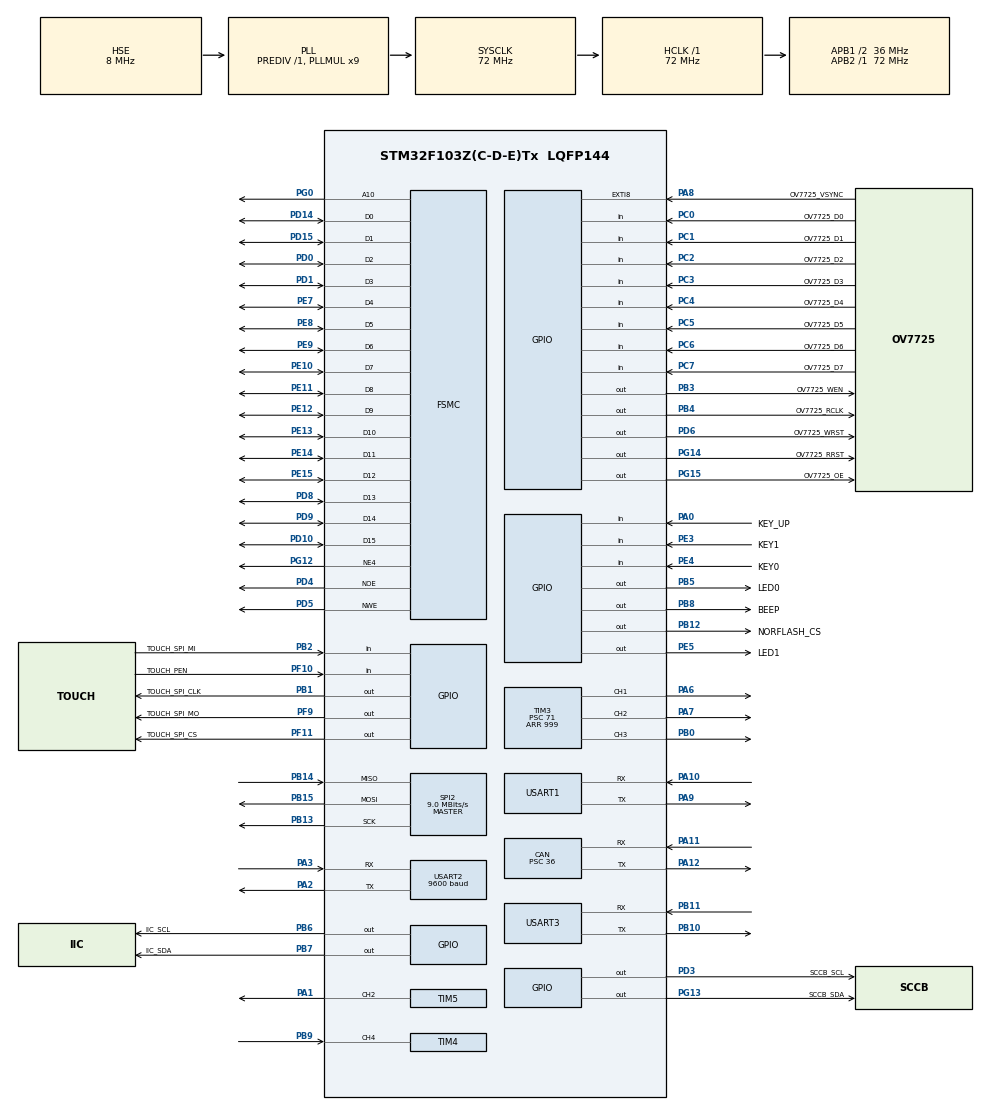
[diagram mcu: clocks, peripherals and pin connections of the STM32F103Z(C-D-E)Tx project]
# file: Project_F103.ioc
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CAN.ABOM=ENABLE
CAN.AWUM=ENABLE
CAN.BS1=CAN_BS1_2TQ
CAN.BS2=CAN_BS2_2TQ
CAN.CalculateBaudRate=200000
CAN.CalculateTimeBit=5000
CAN.CalculateTimeQuantum=1000.0
CAN.Mode=CAN_MODE_NORMAL
CAN.Prescaler=36
Dma.Request0=USART1_RX
Dma.Request1=USART1_TX
Dma.Request2=USART2_RX
Dma.Request3=USART2_TX
Dma.Request4=USART3_RX
Dma.Request5=USART3_TX
Dma.USART1_RX.0.Direction=DMA_PERIPH_TO_MEMORY
Dma.USART1_RX.0.Instance=DMA1_Channel5
Dma.USART1_RX.0.MemDataAlignment=DMA_MDATAALIGN_BYTE
Dma.USART1_RX.0.MemInc=DMA_MINC_ENABLE
Dma.USART1_RX.0.Mode=DMA_NORMAL
Dma.USART1_RX.0.PeriphDataAlignment=DMA_PDATAALIGN_BYTE
Dma.USART1_RX.0.PeriphInc=DMA_PINC_DISABLE
Dma.USART1_RX.0.Priority=DMA_PRIORITY_LOW
Dma.USART1_TX.1.Direction=DMA_MEMORY_TO_PERIPH
Dma.USART1_TX.1.Instance=DMA1_Channel4
Dma.USART1_TX.1.MemDataAlignment=DMA_MDATAALIGN_BYTE
Dma.USART1_TX.1.MemInc=DMA_MINC_ENABLE
Dma.USART1_TX.1.Mode=DMA_NORMAL
Dma.USART1_TX.1.PeriphDataAlignment=DMA_PDATAALIGN_BYTE
Dma.USART1_TX.1.PeriphInc=DMA_PINC_DISABLE
Dma.USART1_TX.1.Priority=DMA_PRIORITY_LOW
Dma.USART2_RX.2.Direction=DMA_PERIPH_TO_MEMORY
Dma.USART2_RX.2.Instance=DMA1_Channel6
Dma.USART2_RX.2.MemDataAlignment=DMA_MDATAALIGN_BYTE
Dma.USART2_RX.2.MemInc=DMA_MINC_ENABLE
Dma.USART2_RX.2.Mode=DMA_NORMAL
Dma.USART2_RX.2.PeriphDataAlignment=DMA_PDATAALIGN_BYTE
Dma.USART2_RX.2.PeriphInc=DMA_PINC_DISABLE
Dma.USART2_RX.2.Priority=DMA_PRIORITY_LOW
Dma.USART2_TX.3.Direction=DMA_MEMORY_TO_PERIPH
Dma.USART2_TX.3.Instance=DMA1_Channel7
Dma.USART2_TX.3.MemDataAlignment=DMA_MDATAALIGN_BYTE
Dma.USART2_TX.3.MemInc=DMA_MINC_ENABLE
Dma.USART2_TX.3.Mode=DMA_NORMAL
Dma.USART2_TX.3.PeriphDataAlignment=DMA_PDATAALIGN_BYTE
Dma.USART2_TX.3.PeriphInc=DMA_PINC_DISABLE
Dma.USART2_TX.3.Priority=DMA_PRIORITY_LOW
Dma.USART3_RX.4.Direction=DMA_PERIPH_TO_MEMORY
Dma.USART3_RX.4.Instance=DMA1_Channel3
Dma.USART3_RX.4.MemDataAlignment=DMA_MDATAALIGN_BYTE
Dma.USART3_RX.4.MemInc=DMA_MINC_ENABLE
Dma.USART3_RX.4.Mode=DMA_NORMAL
Dma.USART3_RX.4.PeriphDataAlignment=DMA_PDATAALIGN_BYTE
Dma.USART3_RX.4.PeriphInc=DMA_PINC_DISABLE
Dma.USART3_RX.4.Priority=DMA_PRIORITY_LOW
Dma.USART3_TX.5.Direction=DMA_MEMORY_TO_PERIPH
Dma.USART3_TX.5.Instance=DMA1_Channel2
Dma.USART3_TX.5.MemDataAlignment=DMA_MDATAALIGN_BYTE
Dma.USART3_TX.5.MemInc=DMA_MINC_ENABLE
Dma.USART3_TX.5.Mode=DMA_NORMAL
Dma.USART3_TX.5.PeriphDataAlignment=DMA_PDATAALIGN_BYTE
Dma.USART3_TX.5.PeriphInc=DMA_PINC_DISABLE
Dma.USART3_TX.5.Priority=DMA_PRIORITY_LOW
FSMC.AddressSetupTime1=0
FSMC.BusTurnAroundDuration1=0
FSMC.DataSetupTime1=15
FSMC.ExtendedAddressSetupTime1=0
FSMC.ExtendedBusTurnAroundDuration1=0
FSMC.ExtendedDataSetupTime1=1
FSMC.ExtendedMode1=FSMC_EXTENDED_MODE_ENABLE
FSMC.WriteOperation1=FSMC_WRITE_OPERATION_ENABLE
IWDG.Prescaler=IWDG_PRESCALER_32
Mcu.Family=STM32F1
Mcu.Name=STM32F103Z(C-D-E)Tx
Mcu.Package=LQFP144
NVIC.CAN1_RX1_IRQn=true\:6\:0\:true\:false\:true\:true\:true\:true
NVIC.DMA1_Channel2_IRQn=true\:0\:0\:false\:false\:true\:false\:true\:true
NVIC.DMA1_Channel3_IRQn=true\:0\:0\:false\:false\:true\:false\:true\:true
NVIC.DMA1_Channel4_IRQn=true\:0\:0\:false\:false\:true\:false\:true\:true
NVIC.DMA1_Channel5_IRQn=true\:0\:0\:false\:false\:true\:false\:true\:true
NVIC.DMA1_Channel6_IRQn=true\:0\:0\:false\:false\:true\:false\:true\:true
NVIC.DMA1_Channel7_IRQn=true\:0\:0\:false\:false\:true\:false\:true\:true
NVIC.EXTI9_5_IRQn=true\:7\:0\:true\:false\:true\:true\:true\:true
NVIC.PriorityGroup=NVIC_PRIORITYGROUP_4
NVIC.TIM4_IRQn=true\:6\:0\:true\:false\:true\:true\:true\:true
NVIC.TIM6_IRQn=true\:15\:0\:false\:false\:true\:false\:true\:true
NVIC.TimeBase=TIM6_IRQn
NVIC.TimeBaseIP=TIM6
NVIC.USART1_IRQn=true\:6\:0\:true\:false\:true\:false\:true\:true
NVIC.USART2_IRQn=true\:6\:0\:true\:false\:true\:true\:true\:true
NVIC.USART3_IRQn=true\:6\:0\:true\:false\:true\:true\:true\:true
NVIC.USB_LP_CAN1_RX0_IRQn=true\:6\:0\:true\:false\:true\:true\:true\:true
OSC_IN.Mode=HSE-External-Oscillator
OSC_IN.Signal=RCC_OSC_IN
OSC_OUT.Mode=HSE-External-Oscillator
OSC_OUT.Signal=RCC_OSC_OUT
PA0-WKUP.GPIO_Label=KEY_UP
PA0-WKUP.GPIO_PuPd=GPIO_PULLUP
PA0-WKUP.Signal=GPIO_Input
PA1.Signal=S_TIM5_CH2
PA10.Mode=Asynchronous
PA10.Signal=USART1_RX
PA11.Mode=CAN_Activate
PA11.Signal=CAN_RX
PA12.Mode=CAN_Activate
PA12.Signal=CAN_TX
PA13.Mode=Serial_Wire
PA13.Signal=SYS_JTMS-SWDIO
PA14.Mode=Serial_Wire
PA14.Signal=SYS_JTCK-SWCLK
PA2.Mode=Asynchronous
PA2.Signal=USART2_TX
PA3.Mode=Asynchronous
PA3.Signal=USART2_RX
PA6.Signal=S_TIM3_CH1
PA7.Signal=S_TIM3_CH2
PA8.GPIO_Label=OV7725_VSYNC
PA8.Signal=GPXTI8
PA9.Mode=Asynchronous
PA9.Signal=USART1_TX
PB0.Signal=S_TIM3_CH3
PB1.GPIO_Label=TOUCH_SPI_CLK
PB1.GPIO_ModeDefaultOutputPP=GPIO_MODE_OUTPUT_PP
PB1.GPIO_PuPd=GPIO_PULLUP
PB1.GPIO_Speed=GPIO_SPEED_FREQ_HIGH
PB1.PinState=GPIO_PIN_SET
PB1.Signal=GPIO_Output
PB10.Mode=Asynchronous
PB10.Signal=USART3_TX
PB11.Mode=Asynchronous
PB11.Signal=USART3_RX
PB12.GPIO_Label=NORFLASH_CS
PB12.GPIO_ModeDefaultOutputPP=GPIO_MODE_OUTPUT_PP
PB12.GPIO_PuPd=GPIO_PULLUP
PB12.GPIO_Speed=GPIO_SPEED_FREQ_HIGH
PB12.PinState=GPIO_PIN_SET
PB12.Signal=GPIO_Output
PB13.Mode=Full_Duplex_Master
PB13.Signal=SPI2_SCK
PB14.Mode=Full_Duplex_Master
PB14.Signal=SPI2_MISO
PB15.Mode=Full_Duplex_Master
PB15.Signal=SPI2_MOSI
PB2.GPIO_Label=TOUCH_SPI_MI
PB2.GPIO_PuPd=GPIO_PULLUP
PB2.Signal=GPIO_Input
PB3.GPIO_Label=OV7725_WEN
PB3.GPIO_ModeDefaultOutputPP=GPIO_MODE_OUTPUT_PP
PB3.GPIO_PuPd=GPIO_PULLUP
PB3.GPIO_Speed=GPIO_SPEED_FREQ_HIGH
PB3.PinState=GPIO_PIN_SET
PB3.Signal=GPIO_Output
PB4.GPIO_Label=OV7725_RCLK
PB4.GPIO_ModeDefaultOutputPP=GPIO_MODE_OUTPUT_PP
PB4.GPIO_PuPd=GPIO_PULLUP
PB4.GPIO_Speed=GPIO_SPEED_FREQ_HIGH
PB4.PinState=GPIO_PIN_SET
PB4.Signal=GPIO_Output
PB5.GPIO_Label=LED0
PB5.GPIO_PuPd=GPIO_NOPULL
PB5.PinState=GPIO_PIN_SET
PB5.Signal=GPIO_Output
PB6.GPIO_Label=IIC_SCL
PB6.GPIO_ModeDefaultOutputPP=GPIO_MODE_OUTPUT_OD
PB6.GPIO_PuPd=GPIO_NOPULL
PB6.GPIO_Speed=GPIO_SPEED_FREQ_HIGH
PB6.PinState=GPIO_PIN_SET
PB6.Signal=GPIO_Output
PB7.GPIO_Label=IIC_SDA
PB7.GPIO_ModeDefaultOutputPP=GPIO_MODE_OUTPUT_OD
PB7.GPIO_PuPd=GPIO_NOPULL
PB7.GPIO_Speed=GPIO_SPEED_FREQ_HIGH
PB7.PinState=GPIO_PIN_SET
PB7.Signal=GPIO_Output
PB8.GPIO_Label=BEEP
PB8.GPIO_PuPd=GPIO_PULLDOWN
PB8.Signal=GPIO_Output
PB9.Signal=S_TIM4_CH4
PC0.GPIO_Label=OV7725_D0
PC0.GPIO_PuPd=GPIO_NOPULL
PC0.Signal=GPIO_Input
PC1.GPIO_Label=OV7725_D1
PC1.GPIO_PuPd=GPIO_NOPULL
PC1.Signal=GPIO_Input
PC14-OSC32_IN.Mode=LSE-External-Oscillator
PC14-OSC32_IN.Signal=RCC_OSC32_IN
PC15-OSC32_OUT.Mode=LSE-External-Oscillator
PC15-OSC32_OUT.Signal=RCC_OSC32_OUT
PC2.GPIO_Label=OV7725_D2
PC2.GPIO_PuPd=GPIO_NOPULL
PC2.Signal=GPIO_Input
PC3.GPIO_Label=OV7725_D3
PC3.GPIO_PuPd=GPIO_NOPULL
PC3.Signal=GPIO_Input
PC4.GPIO_Label=OV7725_D4
PC4.GPIO_PuPd=GPIO_NOPULL
PC4.Signal=GPIO_Input
PC5.GPIO_Label=OV7725_D5
PC5.GPIO_PuPd=GPIO_NOPULL
PC5.Signal=GPIO_Input
PC6.GPIO_Label=OV7725_D6
PC6.GPIO_PuPd=GPIO_NOPULL
PC6.Signal=GPIO_Input
PC7.GPIO_Label=OV7725_D7
PC7.GPIO_PuPd=GPIO_NOPULL
PC7.Signal=GPIO_Input
PD0.Signal=FSMC_D2_DA2
PD1.Signal=FSMC_D3_DA3
PD10.Signal=FSMC_D15_DA15
PD14.Signal=FSMC_D0_DA0
PD15.Signal=FSMC_D1_DA1
PD3.GPIO_Label=SCCB_SCL
PD3.GPIO_ModeDefaultOutputPP=GPIO_MODE_OUTPUT_OD
PD3.GPIO_PuPd=GPIO_NOPULL
PD3.GPIO_Speed=GPIO_SPEED_FREQ_HIGH
PD3.PinState=GPIO_PIN_SET
PD3.Signal=GPIO_Output
PD4.Signal=FSMC_NOE
PD5.Signal=FSMC_NWE
PD6.GPIO_Label=OV7725_WRST
PD6.GPIO_ModeDefaultOutputPP=GPIO_MODE_OUTPUT_PP
PD6.GPIO_PuPd=GPIO_PULLUP
PD6.GPIO_Speed=GPIO_SPEED_FREQ_HIGH
PD6.PinState=GPIO_PIN_SET
PD6.Signal=GPIO_Output
PD8.Signal=FSMC_D13_DA13
PD9.Signal=FSMC_D14_DA14
PE10.Signal=FSMC_D7_DA7
PE11.Signal=FSMC_D8_DA8
PE12.Signal=FSMC_D9_DA9
PE13.Signal=FSMC_D10_DA10
PE14.Signal=FSMC_D11_DA11
PE15.Signal=FSMC_D12_DA12
PE3.GPIO_Label=KEY1
PE3.GPIO_PuPd=GPIO_PULLDOWN
PE3.Signal=GPIO_Input
PE4.GPIO_Label=KEY0
PE4.GPIO_PuPd=GPIO_PULLDOWN
PE4.Signal=GPIO_Input
PE5.GPIO_Label=LED1
PE5.GPIO_PuPd=GPIO_NOPULL
PE5.PinState=GPIO_PIN_SET
PE5.Signal=GPIO_Output
PE7.Signal=FSMC_D4_DA4
PE8.Signal=FSMC_D5_DA5
PE9.Signal=FSMC_D6_DA6
PF10.GPIO_Label=TOUCH_PEN
PF10.GPIO_PuPd=GPIO_PULLUP
PF10.Signal=GPIO_Input
PF11.GPIO_Label=TOUCH_SPI_CS
PF11.GPIO_ModeDefaultOutputPP=GPIO_MODE_OUTPUT_PP
PF11.GPIO_PuPd=GPIO_PULLUP
PF11.GPIO_Speed=GPIO_SPEED_FREQ_HIGH
PF11.PinState=GPIO_PIN_SET
PF11.Signal=GPIO_Output
PF9.GPIO_Label=TOUCH_SPI_MO
PF9.GPIO_ModeDefaultOutputPP=GPIO_MODE_OUTPUT_PP
PF9.GPIO_PuPd=GPIO_PULLUP
PF9.GPIO_Speed=GPIO_SPEED_FREQ_HIGH
PF9.PinState=GPIO_PIN_SET
PF9.Signal=GPIO_Output
PG0.Signal=FSMC_A10
PG12.Mode=NorPsramChipSelect4_1
PG12.Signal=FSMC_NE4
PG13.GPIO_Label=SCCB_SDA
PG13.GPIO_ModeDefaultOutputPP=GPIO_MODE_OUTPUT_OD
PG13.GPIO_PuPd=GPIO_NOPULL
PG13.GPIO_Speed=GPIO_SPEED_FREQ_HIGH
PG13.PinState=GPIO_PIN_SET
PG13.Signal=GPIO_Output
PG14.GPIO_Label=OV7725_RRST
PG14.GPIO_ModeDefaultOutputPP=GPIO_MODE_OUTPUT_PP
PG14.GPIO_PuPd=GPIO_PULLUP
PG14.GPIO_Speed=GPIO_SPEED_FREQ_HIGH
PG14.PinState=GPIO_PIN_SET
PG14.Signal=GPIO_Output
PG15.GPIO_Label=OV7725_OE
PG15.GPIO_PuPd=GPIO_PULLUP
PG15.GPIO_Speed=GPIO_SPEED_FREQ_HIGH
PG15.PinState=GPIO_PIN_SET
PG15.Signal=GPIO_Output
ProjectManager.HeapSize=0x200
ProjectManager.StackSize=0x400
ProjectManager.TargetToolchain=MDK-ARM V5.32
RCC.AHBFreq_Value=72000000
RCC.APB1CLKDivider=RCC_HCLK_DIV2
RCC.APB1Freq_Value=36000000
RCC.APB1TimFreq_Value=72000000
RCC.APB2Freq_Value=72000000
RCC.APB2TimFreq_Value=72000000
RCC.HCLKFreq_Value=72000000
RCC.PLLMUL=RCC_PLL_MUL9
RCC.PLLSourceVirtual=RCC_PLLSOURCE_HSE
RCC.SYSCLKFreq_VALUE=72000000
RCC.SYSCLKSource=RCC_SYSCLKSOURCE_PLLCLK
RCC.USBFreq_Value=72000000
SH.FSMC_A10.0=FSMC_A10,A10_1
SH.FSMC_D0_DA0.0=FSMC_D0,16b-d1
SH.FSMC_D10_DA10.0=FSMC_D10,16b-d1
SH.FSMC_D11_DA11.0=FSMC_D11,16b-d1
SH.FSMC_D12_DA12.0=FSMC_D12,16b-d1
SH.FSMC_D13_DA13.0=FSMC_D13,16b-d1
SH.FSMC_D14_DA14.0=FSMC_D14,16b-d1
SH.FSMC_D15_DA15.0=FSMC_D15,16b-d1
SH.FSMC_D1_DA1.0=FSMC_D1,16b-d1
SH.FSMC_D2_DA2.0=FSMC_D2,16b-d1
SH.FSMC_D3_DA3.0=FSMC_D3,16b-d1
SH.FSMC_D4_DA4.0=FSMC_D4,16b-d1
SH.FSMC_D5_DA5.0=FSMC_D5,16b-d1
SH.FSMC_D6_DA6.0=FSMC_D6,16b-d1
SH.FSMC_D7_DA7.0=FSMC_D7,16b-d1
SH.FSMC_D8_DA8.0=FSMC_D8,16b-d1
SH.FSMC_D9_DA9.0=FSMC_D9,16b-d1
SH.FSMC_NOE.0=FSMC_NOE,Lcd1
SH.FSMC_NWE.0=FSMC_NWE,Lcd1
SH.S_TIM3_CH1.0=TIM3_CH1,PWM Generation1 CH1
SH.S_TIM3_CH2.0=TIM3_CH2,PWM Generation2 CH2
SH.S_TIM3_CH3.0=TIM3_CH3,PWM Generation3 CH3
SH.S_TIM4_CH4.0=TIM4_CH4,Input_Capture4_from_TI4
SH.S_TIM5_CH2.0=TIM5_CH2,PWM Generation2 CH2
SPI2.BaudRatePrescaler=SPI_BAUDRATEPRESCALER_4
SPI2.CLKPhase=SPI_PHASE_2EDGE
SPI2.CLKPolarity=SPI_POLARITY_HIGH
SPI2.CalculateBaudRate=9.0 MBits/s
SPI2.Direction=SPI_DIRECTION_2LINES
SPI2.Mode=SPI_MODE_MASTER
SPI2.VirtualType=VM_MASTER
TIM1.Period=999
TIM1.Prescaler=71
TIM3.Channel-PWM\ Generation1\ CH1=TIM_CHANNEL_1
TIM3.Channel-PWM\ Generation2\ CH2=TIM_CHANNEL_2
TIM3.Channel-PWM\ Generation3\ CH3=TIM_CHANNEL_3
TIM3.Period=999
TIM3.Prescaler=71
TIM4.Channel-Input_Capture4_from_TI4=TIM_CHANNEL_4
TIM4.ICFilter_CH4=3
TIM4.Period=9999
TIM4.Prescaler=71
TIM5.Channel-PWM\ Generation2\ CH2=TIM_CHANNEL_2
TIM5.Period=999
TIM5.Prescaler=71
TIM7.Prescaler=71
USART1.VirtualMode=VM_ASYNC
USART2.BaudRate=9600
USART2.VirtualMode=VM_ASYNC
USART3.VirtualMode=VM_ASYNC
VP_IWDG_VS_IWDG.Mode=IWDG_Activate
VP_SYS_VS_tim6.Mode=TIM6
VP_TIM1_VS_ClockSourceINT.Mode=Internal
VP_TIM4_VS_ClockSourceINT.Mode=Internal
VP_TIM5_VS_ClockSourceINT.Mode=Internal
VP_TIM7_VS_ClockSourceINT.Mode=Enable_Timer
board=custom

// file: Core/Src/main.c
/* USER CODE BEGIN Header */
/**
  ******************************************************************************
  * @file           : main.c
  * @brief          : Main program body
  ******************************************************************************
  * @attention
  *
  * Copyright (c) 2025 STMicroelectronics.
  * All rights reserved.
  *
  * This software is licensed under terms that can be found in the LICENSE file
  * in the root directory of this software component.
  * If no LICENSE file comes with this software, it is provided AS-IS.
  *
  ******************************************************************************
  */
/* USER CODE END Header */
#include "main.h"
#include "can.h"
#include "dma.h"
#include "iwdg.h"
#include "spi.h"
#include "tim.h"
#include "usart.h"
#include "gpio.h"
#include "fsmc.h"

/* USER CODE BEGIN Includes */
#include "task_manage.h"

/* USER CODE END Includes */

/* USER CODE BEGIN PTD */
const char SoftWareID[] = "W023";
/* USER CODE END PTD */

void SystemClock_Config(void);

int main(void)
{

  /* USER CODE BEGIN 1 */
  //SCB->VTOR = APP_START_ADDRESS;
  /* USER CODE END 1 */

  /* MCU Configuration--------------------------------------------------------*/

  /* Reset of all peripherals, Initializes the Flash interface and the Systick. */
  HAL_Init();

  /* Configure the system clock */
  SystemClock_Config();

  /* Initialize all configured peripherals */
  MX_GPIO_Init();
  MX_DMA_Init();
  MX_USART1_UART_Init();
  MX_IWDG_Init();
  MX_SPI2_Init();
  MX_USART2_UART_Init();
  MX_FSMC_Init();
  MX_TIM4_Init();
  MX_TIM3_Init();
  MX_TIM1_Init();
  MX_USART3_UART_Init();
  MX_TIM7_Init();
  MX_CAN_Init();
  MX_TIM5_Init();
  /* USER CODE BEGIN 2 */
  HAL_UARTEx_ReceiveToIdle_DMA(&huart1,gU1RxBuf,U1BUF_MAXSIZE);
  HAL_UARTEx_ReceiveToIdle_DMA(&huart2,gU2RxBuf,U2BUF_MAXSIZE);
  HAL_UARTEx_ReceiveToIdle_DMA(&huart3,gU3RxBuf,U3BUF_MAXSIZE);
  HAL_TIM_IC_Start_IT(&htim4,TIM_CHANNEL_4);
  HAL_TIM_Base_Start(&htim7);
  WCAN_Init();
  AT24Cxx_Init();
  Flash_Init();
  RGB_Init();
  OV7725_Init();
  LCD_Init();
  TJC_Init();

  RootTaskCreate(NULL);
  vTaskStartScheduler();
  /* USER CODE END 2 */

  /* Infinite loop */
  while (1)
  {

  }
}

void SystemClock_Config(void)
{
  RCC_OscInitTypeDef RCC_OscInitStruct = {0};
  RCC_ClkInitTypeDef RCC_ClkInitStruct = {0};

  /** Initializes the RCC Oscillators according to the specified parameters
  * in the RCC_OscInitTypeDef structure.
  */
  RCC_OscInitStruct.OscillatorType = RCC_OSCILLATORTYPE_LSI|RCC_OSCILLATORTYPE_HSE;
  RCC_OscInitStruct.HSEState = RCC_HSE_ON;
  RCC_OscInitStruct.HSEPredivValue = RCC_HSE_PREDIV_DIV1;
  RCC_OscInitStruct.HSIState = RCC_HSI_ON;
  RCC_OscInitStruct.LSIState = RCC_LSI_ON;
  RCC_OscInitStruct.PLL.PLLState = RCC_PLL_ON;
  RCC_OscInitStruct.PLL.PLLSource = RCC_PLLSOURCE_HSE;
  RCC_OscInitStruct.PLL.PLLMUL = RCC_PLL_MUL9;
  if (HAL_RCC_OscConfig(&RCC_OscInitStruct) != HAL_OK)
  {
    Error_Handler();
  }

  /** Initializes the CPU, AHB and APB buses clocks
  */
  RCC_ClkInitStruct.ClockType = RCC_CLOCKTYPE_HCLK|RCC_CLOCKTYPE_SYSCLK
                              |RCC_CLOCKTYPE_PCLK1|RCC_CLOCKTYPE_PCLK2;
  RCC_ClkInitStruct.SYSCLKSource = RCC_SYSCLKSOURCE_PLLCLK;
  RCC_ClkInitStruct.AHBCLKDivider = RCC_SYSCLK_DIV1;
  RCC_ClkInitStruct.APB1CLKDivider = RCC_HCLK_DIV2;
  RCC_ClkInitStruct.APB2CLKDivider = RCC_HCLK_DIV1;

  if (HAL_RCC_ClockConfig(&RCC_ClkInitStruct, FLASH_LATENCY_2) != HAL_OK)
  {
    Error_Handler();
  }
}

void HAL_TIM_PeriodElapsedCallback(TIM_HandleTypeDef *htim)
{
  if (htim->Instance == TIM6)
  {
    HAL_IncTick();
  }
}

void Error_Handler(void)
{
  __disable_irq();
  while (1)
  {
  }
}
